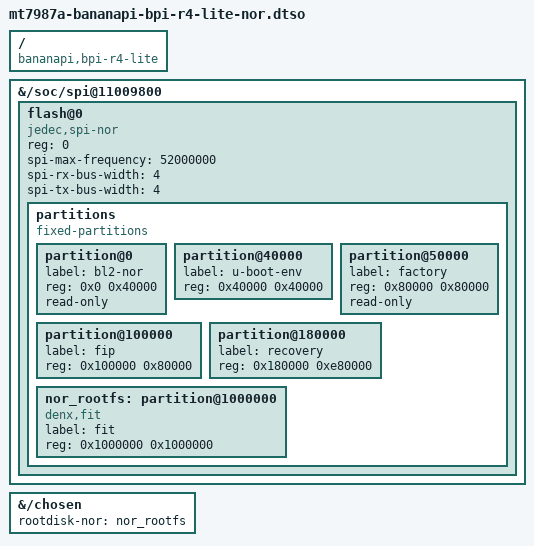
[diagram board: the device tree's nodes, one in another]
/dts-v1/;
/plugin/;

/ {
	compatible = "bananapi,bpi-r4-lite",
		     "mediatek,mt7987a", "mediatek,mt7987";
};

&{/soc/spi@11009800} {
	#address-cells = <1>;
	#size-cells = <0>;

	flash@0 {
		compatible = "jedec,spi-nor";
		reg = <0>;
		spi-max-frequency = <52000000>;
		spi-rx-bus-width = <4>;
		spi-tx-bus-width = <4>;

		partitions {
			compatible = "fixed-partitions";
			#address-cells = <1>;
			#size-cells = <1>;

			partition@0 {
				label = "bl2-nor";
				reg = <0x0 0x40000>;
				read-only;
			};

			partition@40000 {
				label = "u-boot-env";
				reg = <0x40000 0x40000>;
			};

			partition@50000 {
				label = "factory";
				reg = <0x80000 0x80000>;
				read-only;
			};

			partition@100000 {
				label = "fip";
				reg = <0x100000 0x80000>;
			};

			partition@180000 {
				label = "recovery";
				reg = <0x180000 0xe80000>;
			};

			nor_rootfs: partition@1000000 {
				label = "fit";
				reg = <0x1000000 0x1000000>;
				compatible = "denx,fit";
			};
		};
	};
};

&{/chosen} {
	rootdisk-nor = <&nor_rootfs>;
};
